# liliumSOC1_sysctrl register map
Vendor: Nordic Semiconductor; Series: liliumSOC1; File version: 1
Registers are 32-bit, read-write, reset 0x0 unless marked. A register's access mark holds for its fields unless they carry their own. Offsets are from the block's base; [hi:lo] are bit positions; lines under a group give offsets from that group; {n}, {i} and the like mark numbered series; 'fields as' and 'values as' point back to an identical list.

## GLOBAL_TSGEN_NS — GENERIC
Base 0xBF041000
Same registers: GGENERIC18_S 0x5F952000, GLOBAL_ETB_NS 0xBF044000, GLOBAL_ETR_NS 0xBF045000
0x00 TASKS_GENERICTASK wo — Generic event
  [0] TASKS_GENERICTASK
    1=Trigger task
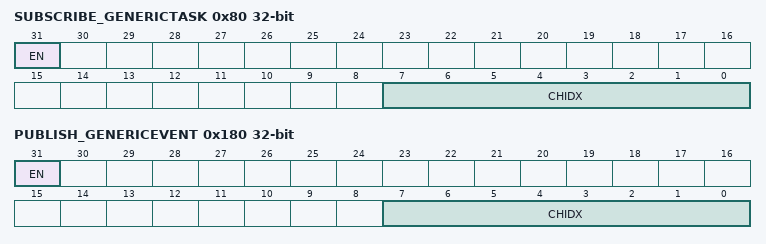
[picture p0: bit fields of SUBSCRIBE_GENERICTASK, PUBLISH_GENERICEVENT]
0x80 SUBSCRIBE_GENERICTASK — Subscribe configuration for task GENERICTASK
  [31] EN
    0=Disabled (Disable subscription); 1=Enabled (Enable subscription)
  [7:0] CHIDX — DPPI channel that task GENERICTASK will subscribe to
0x100 EVENTS_GENERICEVENT — Generic event
  [0] EVENTS_GENERICEVENT
    0=NotGenerated (Event not generated); 1=Generated (Event generated)
0x180 PUBLISH_GENERICEVENT — Publish configuration for event GENERICEVENT
  [31] EN
    0=Disabled (Disable publishing); 1=Enabled (Enable publishing)
  [7:0] CHIDX — DPPI channel that event GENERICEVENT will publish to
0x300 INTEN — Enable or disable interrupt
  [0] GENERICEVENT — Enable or disable interrupt for event GENERICEVENT
    0=Disabled; 1=Enabled
0x304 INTENSET — Enable interrupt
  [0] GENERICEVENT — Write '1' to enable interrupt for event GENERICEVENT
    on read: 0=Disabled (Read: Disabled); 1=Enabled (Read: Enabled) | on write: 1=Set (Enable)
0x308 INTENCLR — Disable interrupt
  [0] GENERICEVENT — Write '1' to disable interrupt for event GENERICEVENT
    on read: 0=Disabled (Read: Disabled); 1=Enabled (Read: Enabled) | on write: 1=Clear (Disable)

## VPRCLIC_S — VPR CLIC registers
Base 0x5F8C8000
0x1000 CLIC group — Unspecified
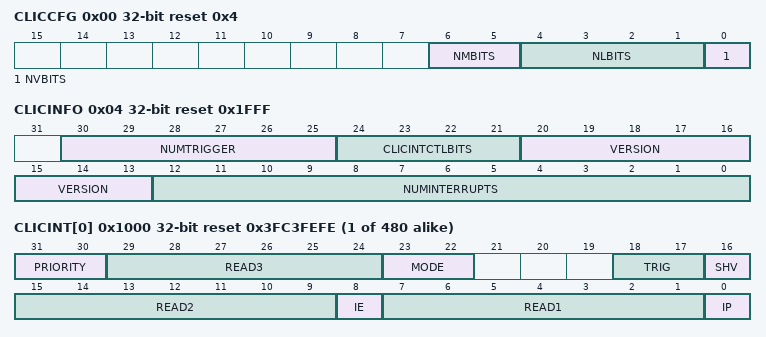
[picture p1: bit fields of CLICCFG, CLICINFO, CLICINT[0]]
  0x00 CLICCFG ro reset 0x4 — CLIC configuration.
    [6:5] NMBITS — Interrupt privilege mode.
      0=ModeM (All interrupts are M-mode only); 1=ModeS (Interrupts can be S-mode); 2=ModeSU (Interrupts can be S-mode or U-mode)
    [4:1] NLBITS — Interrupt level encoding.
    [0] NVBITS — Selective interrupt hardware vectoring.
      0=NotImplemented (Selective interrupt hardware vectoring is not implemented); 1=Implemented (Selective interrupt hardware vectoring is implemented)
  0x04 CLICINFO ro reset 0x1FFF — CLIC information.
    [30:25] NUMTRIGGER — Number of maximum interrupt triggers supported
    [24:21] CLICINTCTLBITS — Implemented bit in the CLICINT.CTL register.
    [20:13] VERSION
    [12:0] NUMINTERRUPTS — Maximum number of interrupts supported.
  {0x1000+4j} CLICINT[{j}] (j=0..479) reset 0x3FC3FEFE — Description collection: Interrupt control register for IRQ number [n].
    [31:30] PRIORITY — Interrupt priority.
    [29:24] READ3 ro — Read as 1, write ignored.
    [23:22] MODE ro — Privilege mode.
      0=UserMode; 1=SupervisorMode; 3=MachineMode
    [18:17] TRIG ro — Trigger type and polarity for each interrupt input.
      0=LevelTriggered (Interrupts are level-triggered); 1=EdgeTriggered (Interrupts are edge-triggered); 2=NegativeLevel (Interrupts are negative level-triggered); 3=NegativeEdge (Interrupts are negative edge-triggered)
    [16] SHV ro — Selective Hardware Vectoring.
      0=NonVectored (Interrupt to be non-vectored); 1=Vectored (Hardware vectored)
    [15:9] READ2 ro — Read as 1, write ignored.
    [8] IE — Interrupt enable bit.
      0=Disabled (Interrupt disabled); 1=Enabled (Interrupt enabled)
    [7:1] READ1 ro — Read as 1, write ignored.
    [0] IP — Interrupt Pending bit.
      0=NotPending (Interrupt not pending); 1=Pending (Interrupt pending)

## GLOBAL_TBM_NS — Trace buffer monitor 0
Base 0xBF003000
Same registers: GLOBAL_TBM_S 0xBF003000 (alternate view of GLOBAL_TBM_NS)
0x00 TASKS_START wo — Start counter
  [0] TASKS_START
    1=Trigger task
0x04 TASKS_STOP wo — Stop counter, clear counter value
  [0] TASKS_STOP
    1=Trigger task
0x08 TASKS_FLUSH wo — Stop counter, keep current counter value
  [0] TASKS_FLUSH
    1=Trigger task
0x100 EVENTS_HALFFULL — Counter value equals half-full
  [0] EVENTS_HALFFULL
    0=NotGenerated (Event not generated); 1=Generated (Event generated)
0x104 EVENTS_FULL — Counter value equals full
  [0] EVENTS_FULL
    values as EVENTS_HALFFULL.EVENTS_HALFFULL
0x108 EVENTS_FLUSH — Counter stopped due to flush
  [0] EVENTS_FLUSH
    values as EVENTS_HALFFULL.EVENTS_HALFFULL
0x200 SHORTS — Shortcuts between local events and tasks
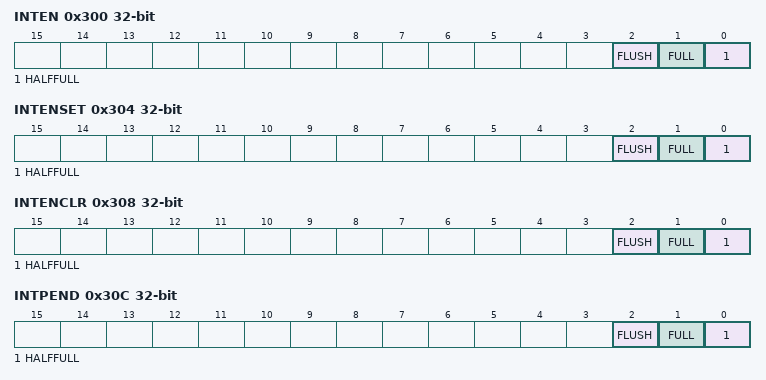
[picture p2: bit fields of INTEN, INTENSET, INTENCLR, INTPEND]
0x300 INTEN — Enable or disable interrupt
  [all] fields
    0=Disabled; 1=Enabled
  [2] FLUSH — Enable or disable interrupt for event FLUSH
  [1] FULL — Enable or disable interrupt for event FULL
  [0] HALFFULL — Enable or disable interrupt for event HALFFULL
0x304 INTENSET — Enable interrupt
  [all] fields
    on read: 0=Disabled (Read: Disabled); 1=Enabled (Read: Enabled) | on write: 1=Set (Enable)
  [2] FLUSH — Write '1' to enable interrupt for event FLUSH
  [1] FULL — Write '1' to enable interrupt for event FULL
  [0] HALFFULL — Write '1' to enable interrupt for event HALFFULL
0x308 INTENCLR — Disable interrupt
  [all] fields
    on read: 0=Disabled (Read: Disabled); 1=Enabled (Read: Enabled) | on write: 1=Clear (Disable)
  [2] FLUSH — Write '1' to disable interrupt for event FLUSH
  [1] FULL — Write '1' to disable interrupt for event FULL
  [0] HALFFULL — Write '1' to disable interrupt for event HALFFULL
0x30C INTPEND ro — Pending interrupts
  [all] fields
    on read: 0=NotPending (Read: Not pending); 1=Pending (Read: Pending)
  [2] FLUSH — Read pending status of interrupt for event FLUSH
  [1] FULL — Read pending status of interrupt for event FULL
  [0] HALFFULL — Read pending status of interrupt for event HALFFULL
0x400 BUFFERSIZE reset 0x1FF — System RAM trace buffer total size in bytes
  [11:0] BUFFERSIZE — Must only be configured in STOP mode. Must be multiple of 16 bytes to make half-buffer size always 64 bit word aligned. BUFFERSIZE LSB byte always fixed as 0xF to 16 bytes boundary. Minimum BUFFERSIZE value 0x00F i.e. 16 bytes, maximum value 0xFFF i.e. 4096 bytes.
    15=Min (16 bytes); 0xFFF=Max (4096 bytes)
0x404 COUNT ro — Counter current value
  [11:0] COUNT
